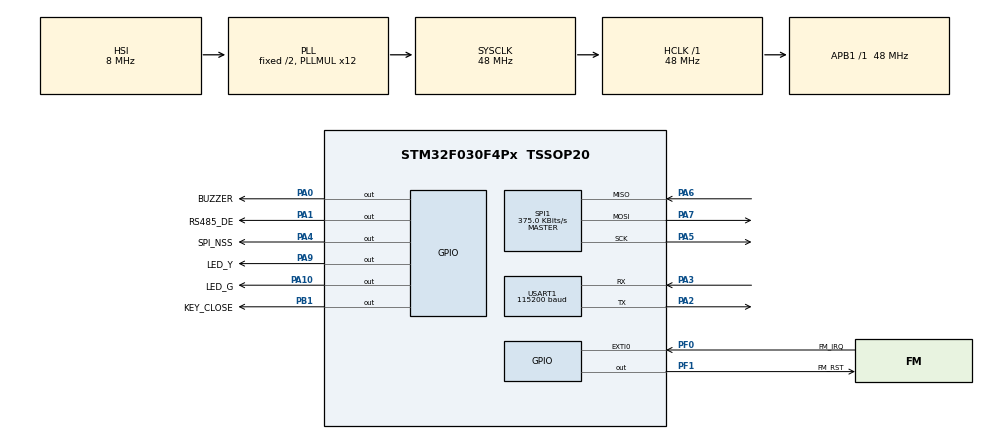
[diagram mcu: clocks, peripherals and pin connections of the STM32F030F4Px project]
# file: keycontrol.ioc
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Mcu.Family=STM32F0
Mcu.Name=STM32F030F4Px
Mcu.Package=TSSOP20
NVIC.EXTI0_1_IRQn=true\:0\:0\:false\:false\:true\:true\:true
NVIC.USART1_IRQn=true\:0\:0\:false\:false\:true\:true\:true
PA0.GPIO_Label=BUZZER
PA0.Signal=GPIO_Output
PA1.GPIO_Label=RS485_DE
PA1.Signal=GPIO_Output
PA10.GPIO_Label=LED_G
PA10.Signal=GPIO_Output
PA13.Mode=Serial_Wire
PA13.Signal=SYS_SWDIO
PA14.Mode=Serial_Wire
PA14.Signal=SYS_SWCLK
PA2.Mode=Asynchronous
PA2.Signal=USART1_TX
PA3.Mode=Asynchronous
PA3.Signal=USART1_RX
PA4.GPIO_Label=SPI_NSS
PA4.Signal=GPIO_Output
PA5.Mode=Full_Duplex_Master
PA5.Signal=SPI1_SCK
PA6.Mode=Full_Duplex_Master
PA6.Signal=SPI1_MISO
PA7.Mode=Full_Duplex_Master
PA7.Signal=SPI1_MOSI
PA9.GPIO_Label=LED_Y
PA9.Signal=GPIO_Output
PB1.GPIO_Label=KEY_CLOSE
PB1.Signal=GPIO_Output
PF0-OSC_IN.GPIO_Label=FM_IRQ
PF0-OSC_IN.Signal=GPXTI0
PF1-OSC_OUT.GPIO_Label=FM_RST
PF1-OSC_OUT.Signal=GPIO_Output
ProjectManager.HeapSize=0x200
ProjectManager.StackSize=0x400
ProjectManager.TargetToolchain=MDK-ARM V5
RCC.AHBFreq_Value=48000000
RCC.APB1Freq_Value=48000000
RCC.APB1TimFreq_Value=48000000
RCC.HCLKFreq_Value=48000000
RCC.PLLMUL=RCC_PLL_MUL12
RCC.SYSCLKFreq_VALUE=48000000
RCC.SYSCLKSource=RCC_SYSCLKSOURCE_PLLCLK
SPI1.BaudRatePrescaler=SPI_BAUDRATEPRESCALER_128
SPI1.CLKPhase=SPI_PHASE_1EDGE
SPI1.CLKPolarity=SPI_POLARITY_LOW
SPI1.CalculateBaudRate=375.0 KBits/s
SPI1.DataSize=SPI_DATASIZE_8BIT
SPI1.Direction=SPI_DIRECTION_2LINES
SPI1.FirstBit=SPI_FIRSTBIT_MSB
SPI1.Mode=SPI_MODE_MASTER
SPI1.NSSPMode=SPI_NSS_PULSE_DISABLE
SPI1.VirtualType=VM_MASTER
USART1.BaudRate=115200
USART1.VirtualMode-Asynchronous=VM_ASYNC
board=custom

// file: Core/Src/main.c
/* USER CODE BEGIN Header */
/**
  ******************************************************************************
  * @file           : main.c
  * @brief          : Main program body
  ******************************************************************************
  * @attention
  *
  * <h2><center>&copy; Copyright (c) 2019 STMicroelectronics.
  * All rights reserved.</center></h2>
  *
  * This software component is licensed by ST under BSD 3-Clause license,
  * the "License"; You may not use this file except in compliance with the
  * License. You may obtain a copy of the License at:
  *                        opensource.org/licenses/BSD-3-Clause
  *
  ******************************************************************************
  */
/* USER CODE END Header */

#include "main.h"

/* USER CODE BEGIN PTD */
static AppTask_t app;//remote pull test
/* USER CODE END PTD */

SPI_HandleTypeDef hspi1;

UART_HandleTypeDef huart1;

void SystemClock_Config(void);
static void MX_GPIO_Init(void);
static void MX_SPI1_Init(void);
static void MX_USART1_UART_Init(void);
/* USER CODE BEGIN PFP */
void MXUsart1UartInit(void)  {MX_USART1_UART_Init();}
/* USER CODE END PFP */

/* USER CODE BEGIN 0 */
void RfidSPIInit(void)
{
  HAL_SPI_DeInit(&hspi1);
  MX_SPI1_Init();
}

static void TimerCountsHandler(void)
{
  if(app.Timer_Mark.Time_1ms_Mark)
  {
      app.Timer_Mark.Time_1ms_Mark=FALSE;
      app.Timer_Counts.rfid_counts_1ms++;
      app.Timer_Counts.rs485_counts_1ms++;
      app.Timer_Counts.led_counts_1ms++;
      app.Timer_Counts.buzzer_counts_1ms++;
  }
}

AppTask_t *getApp(void)
{
    return &app;
}

static void AppParaInit(void)
{
  app.version = 001;
  SystemLoadActionParamOnce();
  // actionPara.seq = 3;
}
/* USER CODE END 0 */

int main(void)
{

  /* MCU Configuration--------------------------------------------------------*/

  /* Reset of all peripherals, Initializes the Flash interface and the Systick. */
  HAL_Init();

  /* Configure the system clock */
  SystemClock_Config();

  /* Initialize all configured peripherals */
  MX_GPIO_Init();
  MX_SPI1_Init();
  MX_USART1_UART_Init();
  /* USER CODE BEGIN 2 */
  AppParaInit();
  app.AppStatus = poweringOn;
  /* USER CODE END 2 */

  /* Infinite loop */
  while (1)
  {

    /* USER CODE BEGIN 3 */
	  TimerCountsHandler();
    RfidMgrHandle();
    Rs485MgrHandle();
    LedMgrHandle();
    // BuzzMgrHandle();
  }
  /* USER CODE END 3 */
}

void SystemClock_Config(void)
{
  RCC_OscInitTypeDef RCC_OscInitStruct = {0};
  RCC_ClkInitTypeDef RCC_ClkInitStruct = {0};
  RCC_PeriphCLKInitTypeDef PeriphClkInit = {0};

  /** Initializes the CPU, AHB and APB busses clocks
  */
  RCC_OscInitStruct.OscillatorType = RCC_OSCILLATORTYPE_HSI;
  RCC_OscInitStruct.HSIState = RCC_HSI_ON;
  RCC_OscInitStruct.HSICalibrationValue = RCC_HSICALIBRATION_DEFAULT;
  RCC_OscInitStruct.PLL.PLLState = RCC_PLL_ON;
  RCC_OscInitStruct.PLL.PLLSource = RCC_PLLSOURCE_HSI;
  RCC_OscInitStruct.PLL.PLLMUL = RCC_PLL_MUL12;
  RCC_OscInitStruct.PLL.PREDIV = RCC_PREDIV_DIV1;
  if (HAL_RCC_OscConfig(&RCC_OscInitStruct) != HAL_OK)
  {
    Error_Handler();
  }
  /** Initializes the CPU, AHB and APB busses clocks
  */
  RCC_ClkInitStruct.ClockType = RCC_CLOCKTYPE_HCLK|RCC_CLOCKTYPE_SYSCLK
                              |RCC_CLOCKTYPE_PCLK1;
  RCC_ClkInitStruct.SYSCLKSource = RCC_SYSCLKSOURCE_PLLCLK;
  RCC_ClkInitStruct.AHBCLKDivider = RCC_SYSCLK_DIV1;
  RCC_ClkInitStruct.APB1CLKDivider = RCC_HCLK_DIV1;

  if (HAL_RCC_ClockConfig(&RCC_ClkInitStruct, FLASH_LATENCY_1) != HAL_OK)
  {
    Error_Handler();
  }
  PeriphClkInit.PeriphClockSelection = RCC_PERIPHCLK_USART1;
  PeriphClkInit.Usart1ClockSelection = RCC_USART1CLKSOURCE_PCLK1;
  if (HAL_RCCEx_PeriphCLKConfig(&PeriphClkInit) != HAL_OK)
  {
    Error_Handler();
  }
}

static void MX_SPI1_Init(void)
{

  /* SPI1 parameter configuration*/
  hspi1.Instance = SPI1;
  hspi1.Init.Mode = SPI_MODE_MASTER;
  hspi1.Init.Direction = SPI_DIRECTION_2LINES;
  hspi1.Init.DataSize = SPI_DATASIZE_8BIT;
  hspi1.Init.CLKPolarity = SPI_POLARITY_LOW;
  hspi1.Init.CLKPhase = SPI_PHASE_1EDGE;
  hspi1.Init.NSS = SPI_NSS_SOFT;
  hspi1.Init.BaudRatePrescaler = SPI_BAUDRATEPRESCALER_128;
  hspi1.Init.FirstBit = SPI_FIRSTBIT_MSB;
  hspi1.Init.TIMode = SPI_TIMODE_DISABLE;
  hspi1.Init.CRCCalculation = SPI_CRCCALCULATION_DISABLE;
  hspi1.Init.CRCPolynomial = 7;
  hspi1.Init.CRCLength = SPI_CRC_LENGTH_DATASIZE;
  hspi1.Init.NSSPMode = SPI_NSS_PULSE_DISABLE;
  if (HAL_SPI_Init(&hspi1) != HAL_OK)
  {
    Error_Handler();
  }

}

static void MX_USART1_UART_Init(void)
{

  huart1.Instance = USART1;
  huart1.Init.BaudRate = 115200;
  huart1.Init.WordLength = UART_WORDLENGTH_8B;
  huart1.Init.StopBits = UART_STOPBITS_1;
  huart1.Init.Parity = UART_PARITY_NONE;
  huart1.Init.Mode = UART_MODE_TX_RX;
  huart1.Init.HwFlowCtl = UART_HWCONTROL_NONE;
  huart1.Init.OverSampling = UART_OVERSAMPLING_16;
  huart1.Init.OneBitSampling = UART_ONE_BIT_SAMPLE_DISABLE;
  huart1.AdvancedInit.AdvFeatureInit = UART_ADVFEATURE_NO_INIT;
  if (HAL_UART_Init(&huart1) != HAL_OK)
  {
    Error_Handler();
  }

}

static void MX_GPIO_Init(void)
{
  GPIO_InitTypeDef GPIO_InitStruct = {0};

  /* GPIO Ports Clock Enable */
  __HAL_RCC_GPIOF_CLK_ENABLE();
  __HAL_RCC_GPIOA_CLK_ENABLE();
  __HAL_RCC_GPIOB_CLK_ENABLE();

  /*Configure GPIO pin Output Level */
  HAL_GPIO_WritePin(FM_RST_GPIO_Port, FM_RST_Pin, GPIO_PIN_RESET);

  /*Configure GPIO pin Output Level */
  HAL_GPIO_WritePin(GPIOA, BUZZER_Pin|RS485_DE_Pin|SPI_NSS_Pin|LED_Y_Pin
                          |LED_G_Pin, GPIO_PIN_RESET);

  /*Configure GPIO pin Output Level */
  HAL_GPIO_WritePin(KEY_ON_GPIO_Port, KEY_ON_Pin, GPIO_PIN_RESET);

  /*Configure GPIO pin : FM_IRQ_Pin */
  GPIO_InitStruct.Pin = FM_IRQ_Pin;
  GPIO_InitStruct.Mode = GPIO_MODE_IT_RISING;
  GPIO_InitStruct.Pull = GPIO_NOPULL;
  HAL_GPIO_Init(FM_IRQ_GPIO_Port, &GPIO_InitStruct);

  /*Configure GPIO pin : FM_RST_Pin */
  GPIO_InitStruct.Pin = FM_RST_Pin;
  GPIO_InitStruct.Mode = GPIO_MODE_OUTPUT_PP;
  GPIO_InitStruct.Pull = GPIO_NOPULL;
  GPIO_InitStruct.Speed = GPIO_SPEED_FREQ_LOW;
  HAL_GPIO_Init(FM_RST_GPIO_Port, &GPIO_InitStruct);

  /*Configure GPIO pins : BUZZER_Pin RS485_DE_Pin SPI_NSS_Pin LED_Y_Pin
                           LED_G_Pin */
  GPIO_InitStruct.Pin = BUZZER_Pin|RS485_DE_Pin|SPI_NSS_Pin|LED_Y_Pin
                          |LED_G_Pin;
  GPIO_InitStruct.Mode = GPIO_MODE_OUTPUT_PP;
  GPIO_InitStruct.Pull = GPIO_NOPULL;
  GPIO_InitStruct.Speed = GPIO_SPEED_FREQ_LOW;
  HAL_GPIO_Init(GPIOA, &GPIO_InitStruct);

  /*Configure GPIO pin : KEY_ON_Pin */
  GPIO_InitStruct.Pin = KEY_ON_Pin;
  GPIO_InitStruct.Mode = GPIO_MODE_OUTPUT_PP;
  GPIO_InitStruct.Pull = GPIO_NOPULL;
  GPIO_InitStruct.Speed = GPIO_SPEED_FREQ_LOW;
  HAL_GPIO_Init(KEY_ON_GPIO_Port, &GPIO_InitStruct);

  /* EXTI interrupt init*/
  HAL_NVIC_SetPriority(EXTI0_1_IRQn, 0, 0);
  HAL_NVIC_EnableIRQ(EXTI0_1_IRQn);
  // LED_G_ON();
  // HAL_GPIO_WritePin(GPIOA, LED_G_Pin, GPIO_PIN_SET);

}

void Error_Handler(void)
{
}

/************************ (C) COPYRIGHT STMicroelectronics *****END OF FILE****/
